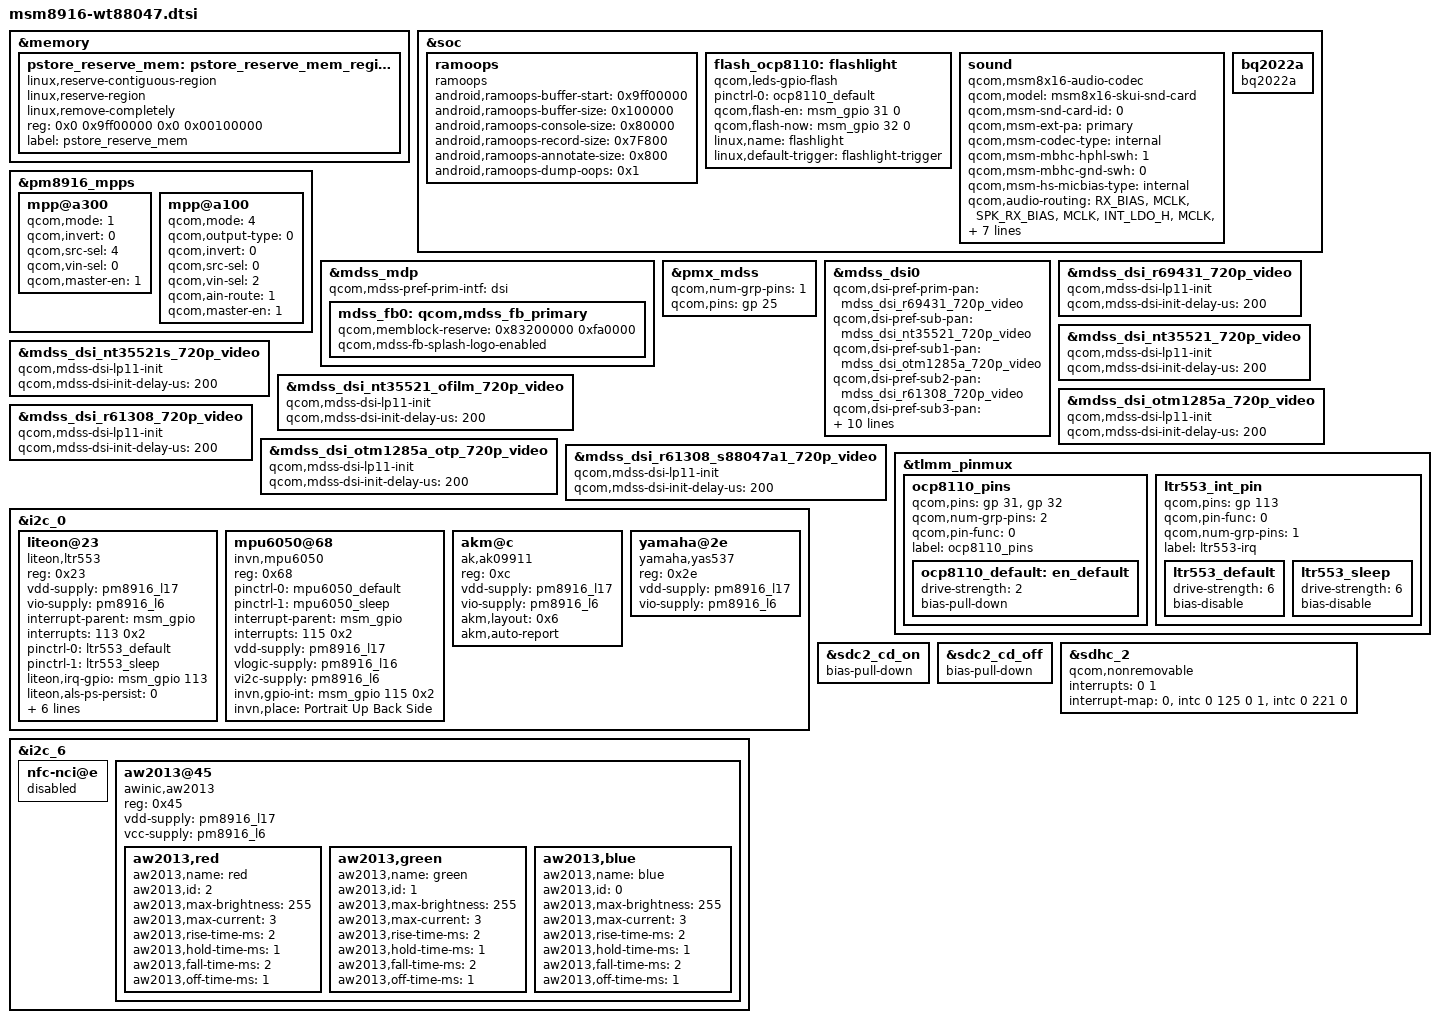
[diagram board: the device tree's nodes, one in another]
/* Copyright (c) 2015, The Linux Foundation. All rights reserved.
 *
 * This program is free software; you can redistribute it and/or modify
 * it under the terms of the GNU General Public License version 2 and
 * only version 2 as published by the Free Software Foundation.
 *
 * This program is distributed in the hope that it will be useful,
 * but WITHOUT ANY WARRANTY; without even the implied warranty of
 * MERCHANTABILITY or FITNESS FOR A PARTICULAR PURPOSE.  See the
 * GNU General Public License for more details.
 */

#include "dsi-panel-r69431-720p-video.dtsi"
#include "dsi-panel-nt35521-720p-video.dtsi"
#include "dsi-panel-nt35521s-720p-video.dtsi"
#include "dsi-panel-nt35521-ofilm-720p-video.dtsi"
#include "dsi-panel-otm1285a-720p-video.dtsi"
#include "dsi-panel-r61308-720p-video.dtsi"
#include "dsi-panel-otm1285a-otp-720p-video.dtsi"
#include "dsi-panel-r61308-s88047a1-720p-video.dtsi"
#include "msm8916-camera-sensor-wt88047.dtsi"

&memory {
	pstore_reserve_mem: pstore_reserve_mem_region@0 {
		linux,reserve-contiguous-region;
		linux,reserve-region;
		linux,remove-completely;
		reg = <0x0 0x9ff00000 0x0 0x00100000>;
		label = "pstore_reserve_mem";
	};
};

&soc {
	ramoops {
		compatible = "ramoops";
		status = "ok";

		android,ramoops-buffer-start = <0x9ff00000>;
		android,ramoops-buffer-size = <0x100000>;
		android,ramoops-console-size = <0x80000>;
		android,ramoops-record-size = <0x7F800>;
		android,ramoops-annotate-size = <0x800>;
		android,ramoops-dump-oops = <0x1>;
	};

	flash_ocp8110:flashlight {
		compatible = "qcom,leds-gpio-flash";
		status = "okay";
		pinctrl-names = "ocp8110_default";
		pinctrl-0 = <&ocp8110_default>;
		qcom,flash-en = <&msm_gpio 31 0>;
		qcom,flash-now = <&msm_gpio 32 0>;
		linux,name = "flashlight";
		linux,default-trigger = "flashlight-trigger";
	};

	sound {
		compatible = "qcom,msm8x16-audio-codec";
		qcom,model = "msm8x16-skui-snd-card";
		qcom,msm-snd-card-id = <0>;
		qcom,msm-ext-pa = "primary";
		qcom,msm-codec-type = "internal";
		qcom,msm-mbhc-hphl-swh = <1>;
		qcom,msm-mbhc-gnd-swh = <0>;
		qcom,msm-hs-micbias-type = "internal";
		qcom,audio-routing =
			"RX_BIAS", "MCLK",
			"SPK_RX_BIAS", "MCLK",
			"INT_LDO_H", "MCLK",
			"MIC BIAS External", "Handset Mic",
			"MIC BIAS Internal2", "Headset Mic",
			"MIC BIAS External", "Secondary Mic",
			"AMIC1", "MIC BIAS External",
			"AMIC2", "MIC BIAS Internal2",
			"AMIC3", "MIC BIAS External";
		pinctrl-names = "cdc_lines_act",
				"cdc_lines_sus";
		pinctrl-0 = <&cdc_pdm_lines_act>;
		pinctrl-1 = <&cdc_pdm_lines_sus>;
	};

	bq2022a {
		compatible = "bq2022a";
		status= "okay";
	};

};

&pm8916_mpps {
	mpp@a300 { /* MPP 4 */
		/* Backlight PWM */
		qcom,mode = <1>;		/* Digital output */
		qcom,invert = <0>;		/* Disable Invert */
		qcom,src-sel = <4>;		/* DTEST1 */
		qcom,vin-sel = <0>;		/* VPH_PWR */
		qcom,master-en = <1>;		/* Enable MPP */
	};

	mpp@a100 { /* MPP 2 */
		/* HR LED */
		qcom,mode = <4>;
		qcom,output-type = <0>;
		qcom,invert = <0>;
		qcom,src-sel = <0>;
		qcom,vin-sel = <2>;
		qcom,ain-route = <1>;
		qcom,master-en = <1>;
	};
};

&mdss_mdp {
	qcom,mdss-pref-prim-intf = "dsi";

	mdss_fb0: qcom,mdss_fb_primary {
		qcom,memblock-reserve = <0x83200000 0xfa0000>;
		qcom,mdss-fb-splash-logo-enabled;
	};
};

&pmx_mdss {
	qcom,num-grp-pins = <1>;
	qcom,pins = <&gp 25>;
};

&mdss_dsi0 {
	qcom,dsi-pref-prim-pan = <&mdss_dsi_r69431_720p_video>;
	qcom,dsi-pref-sub-pan = <&mdss_dsi_nt35521_720p_video>;
	qcom,dsi-pref-sub1-pan = <&mdss_dsi_otm1285a_720p_video>;
	qcom,dsi-pref-sub2-pan = <&mdss_dsi_r61308_720p_video>;
	qcom,dsi-pref-sub3-pan = <&mdss_dsi_otm1285a_otp_720p_video>;
	qcom,dsi-pref-sub4-pan = <&mdss_dsi_r61308_s88047a1_720p_video>;
	qcom,dsi-pref-sub5-pan = <&mdss_dsi_nt35521s_720p_video>;
	qcom,dsi-pref-sub6-pan = <&mdss_dsi_nt35521_ofilm_720p_video>;
	pinctrl-names = "mdss_default", "mdss_sleep";
	pinctrl-0 = <&mdss_dsi_active>;
	pinctrl-1 = <&mdss_dsi_suspend>;

	qcom,platform-reset-gpio = <&msm_gpio 25 0>;
};

&mdss_dsi_r69431_720p_video {
	/* qcom,cont-splash-enabled; */
	qcom,mdss-dsi-lp11-init;
	qcom,mdss-dsi-init-delay-us = <200>;
};

&mdss_dsi_nt35521_720p_video {
	/* qcom,cont-splash-enabled; */
	qcom,mdss-dsi-lp11-init;
	qcom,mdss-dsi-init-delay-us = <200>;
};

&mdss_dsi_nt35521s_720p_video {
	/* qcom,cont-splash-enabled; */
	qcom,mdss-dsi-lp11-init;
	qcom,mdss-dsi-init-delay-us = <200>;
};

&mdss_dsi_nt35521_ofilm_720p_video {
	/* qcom,cont-splash-enabled; */
	qcom,mdss-dsi-lp11-init;
	qcom,mdss-dsi-init-delay-us = <200>;
};

&mdss_dsi_otm1285a_720p_video {
	/* qcom,cont-splash-enabled; */
	qcom,mdss-dsi-lp11-init;
	qcom,mdss-dsi-init-delay-us = <200>;
};

&mdss_dsi_r61308_720p_video {
	/* qcom,esd-check-enabled; */
	/* qcom,cont-splash-enabled; */
	qcom,mdss-dsi-lp11-init;
	qcom,mdss-dsi-init-delay-us = <200>;
};

&mdss_dsi_otm1285a_otp_720p_video {
	/* qcom,cont-splash-enabled; */
	qcom,mdss-dsi-lp11-init;
	qcom,mdss-dsi-init-delay-us = <200>;
};

&mdss_dsi_r61308_s88047a1_720p_video {
	/* qcom,esd-check-enabled; */
	/* qcom,cont-splash-enabled; */
	qcom,mdss-dsi-lp11-init;
	qcom,mdss-dsi-init-delay-us = <200>;
};

&tlmm_pinmux {
	ocp8110_pins {
		qcom,pins = <&gp 31>, <&gp 32>;
		qcom,num-grp-pins = <2>;
		qcom,pin-func = <0>;
		label = "ocp8110_pins";
		ocp8110_default: en_default {
			  drive-strength = <2>;
			  bias-pull-down;
		};
	};

	ltr553_int_pin {
		qcom,pins = <&gp 113>;
		qcom,pin-func = <0>;
		qcom,num-grp-pins = <1>;
		label = "ltr553-irq";
		ltr553_default: ltr553_default {
			drive-strength = <6>;
			bias-disable;
		};
		ltr553_sleep: ltr553_sleep {
			drive-strength = <6>;
			bias-disable;
		};
	};
};

&i2c_0 { /* BLSP1 QUP2 */
	liteon@23 {
		compatible = "liteon,ltr553";
		reg = <0x23>;
		vdd-supply = <&pm8916_l17>;
		vio-supply = <&pm8916_l6>;
		interrupt-parent = <&msm_gpio>;
		interrupts = <113 0x2>;
		pinctrl-names = "default","sleep";
		pinctrl-0 = <&ltr553_default>;
		pinctrl-1 = <&ltr553_sleep>;
		liteon,irq-gpio = <&msm_gpio 113 0x2>;
		liteon,als-ps-persist = <0>;
		liteon,ps-led = <0x7f>;
		liteon,ps-pulses = <4>;
		liteon,wakeup-threshold = <4>;
		liteon,als-integration-time = <0>;
		liteon,als-sensitivity = <6000 3200 1600 800 0 0 130 1>;
	};

	mpu6050@68 {
		compatible = "invn,mpu6050";
		reg = <0x68>;
		pinctrl-names = "mpu_default","mpu_sleep";
		pinctrl-0 = <&mpu6050_default>;
		pinctrl-1 = <&mpu6050_sleep>;
		interrupt-parent = <&msm_gpio>;
		interrupts = <115 0x2>;
		vdd-supply = <&pm8916_l17>;
		vlogic-supply = <&pm8916_l16>;
		vi2c-supply = <&pm8916_l6>;
		invn,gpio-int = <&msm_gpio 115 0x2>;
		invn,place = "Portrait Up Back Side";
	};

	akm@c {
		compatible = "ak,ak09911";
		reg = <0xc>;
		vdd-supply = <&pm8916_l17>;
		vio-supply = <&pm8916_l6>;
		akm,layout = <0x6>;
		akm,auto-report;
	};

	yamaha@2e {
		compatible = "yamaha,yas537";
		reg = <0x2e>;
		vdd-supply = <&pm8916_l17>;
		vio-supply = <&pm8916_l6>;
	};
};

&i2c_6 { /* BLSP1 QUP6 */
	nfc-nci@e {
		status = "disabled";
	};

	aw2013@45 {
		compatible = "awinic,aw2013";
		reg = <0x45>;
		vdd-supply = <&pm8916_l17>;
		vcc-supply = <&pm8916_l6>;

		aw2013,red {
			aw2013,name = "red";
			aw2013,id = <2>;
			aw2013,max-brightness = <255>;
			aw2013,max-current = <3>;
			aw2013,rise-time-ms = <2>;
			aw2013,hold-time-ms = <1>;
			aw2013,fall-time-ms = <2>;
			aw2013,off-time-ms = <1>;
		};

		aw2013,green {
			aw2013,name = "green";
			aw2013,id = <1>;
			aw2013,max-brightness = <255>;
			aw2013,max-current = <3>;
			aw2013,rise-time-ms = <2>;
			aw2013,hold-time-ms = <1>;
			aw2013,fall-time-ms = <2>;
			aw2013,off-time-ms = <1>;
		};

		aw2013,blue {
			aw2013,name = "blue";
			aw2013,id = <0>;
			aw2013,max-brightness = <255>;
			aw2013,max-current = <3>;
			aw2013,rise-time-ms = <2>;
			aw2013,hold-time-ms = <1>;
			aw2013,fall-time-ms = <2>;
			aw2013,off-time-ms = <1>;
		};
	};
};

&sdc2_cd_on {
	/delete-property/ bias-pull-up;
	bias-pull-down;
};

&sdc2_cd_off {
	/delete-property/ bias-disable;
	bias-pull-down;
};

&sdhc_2 {
	qcom,nonremovable;

	interrupts = <0 1>;
	interrupt-map = <0 &intc 0 125 0
		1 &intc 0 221 0>;
	interrupt-names = "hc_irq", "pwr_irq";
	/delete-property/ cd-gpios;
};
